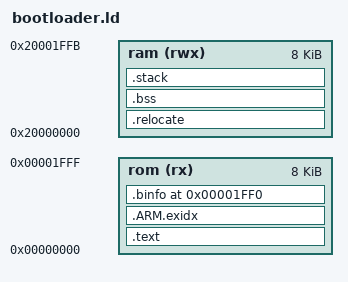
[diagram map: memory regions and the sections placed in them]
/* Bootloader linker script for the ATSAMD21E16B (lcj-standard).
 *
 * Derived from scripts/samd21j18a.ld with MEMORY right-sized: 64 KB flash /
 * 8 KB SRAM (the upstream script assumes a J18A's 256 KB / 32 KB). The
 * bootloader still occupies the bottom 8 KB of flash. The last RAM word is
 * the DBL_TAP boot-magic slot; the stack section sits after .bss and never
 * reaches it, but keep RAM LENGTH 4 bytes short as a belt-and-braces measure.
 */

OUTPUT_FORMAT("elf32-littlearm", "elf32-littlearm", "elf32-littlearm")
OUTPUT_ARCH(arm)
SEARCH_DIR(.)

/* Memory Spaces Definitions */
MEMORY
{
  rom      (rx)  : ORIGIN = 0x00000000, LENGTH = 0x00002000
  ram      (rwx) : ORIGIN = 0x20000000, LENGTH = 0x00002000 - 4
}

/* The stack size used by the application. NOTE: you need to adjust according to your application. */
STACK_SIZE = DEFINED(STACK_SIZE) ? STACK_SIZE : DEFINED(__stack_size__) ? __stack_size__ : 0x1000;

/* Section Definitions */
SECTIONS
{
    .text :
    {
        . = ALIGN(4);
        _sfixed = .;
        KEEP(*(.vectors .vectors.*))
        *(.text .text.* .gnu.linkonce.t.*)
        *(.glue_7t) *(.glue_7)
        *(.rodata .rodata* .gnu.linkonce.r.*)
        *(.ARM.extab* .gnu.linkonce.armextab.*)

        /* Support C constructors, and C destructors in both user code
           and the C library. This also provides support for C++ code. */
        . = ALIGN(4);
        KEEP(*(.init))
        . = ALIGN(4);
        __preinit_array_start = .;
        KEEP (*(.preinit_array))
        __preinit_array_end = .;

        . = ALIGN(4);
        __init_array_start = .;
        KEEP (*(SORT(.init_array.*)))
        KEEP (*(.init_array))
        __init_array_end = .;

        . = ALIGN(4);
        KEEP (*crtbegin.o(.ctors))
        KEEP (*(EXCLUDE_FILE (*crtend.o) .ctors))
        KEEP (*(SORT(.ctors.*)))
        KEEP (*crtend.o(.ctors))

        . = ALIGN(4);
        _efixed = .;            /* End of text section */
    } > rom

    /* .ARM.exidx is sorted, so has to go in its own output section.  */
    PROVIDE_HIDDEN (__exidx_start = .);
    .ARM.exidx :
    {
      *(.ARM.exidx* .gnu.linkonce.armexidx.*)
    } > rom
    PROVIDE_HIDDEN (__exidx_end = .);

    . = ALIGN(4);
    _etext = .;

    .relocate : AT (_etext)
    {
        . = ALIGN(4);
        _srelocate = .;
        *(.ramfunc .ramfunc.*);
        *(.data .data.*);
        . = ALIGN(4);
        _erelocate = .;
    } > ram

    /* .bss section which is used for uninitialized data */
    .bss (NOLOAD) :
    {
        . = ALIGN(4);
        _sbss = . ;
        _szero = .;
        *(.bss .bss.*)
        *(COMMON)
        . = ALIGN(4);
        _ebss = . ;
        _ezero = .;
    } > ram

    /* stack section */
    .stack (NOLOAD):
    {
        . = ALIGN(8);
        _sstack = .;
        . = . + STACK_SIZE;
        . = ALIGN(8);
        _estack = .;
    } > ram

    . = ALIGN(4);
    _end = . ;

    _binfo_start = 0x00002000 - 4 * 4;
    .binfo _binfo_start : {
      KEEP(*(.binfo)) ;
    } > rom
}
